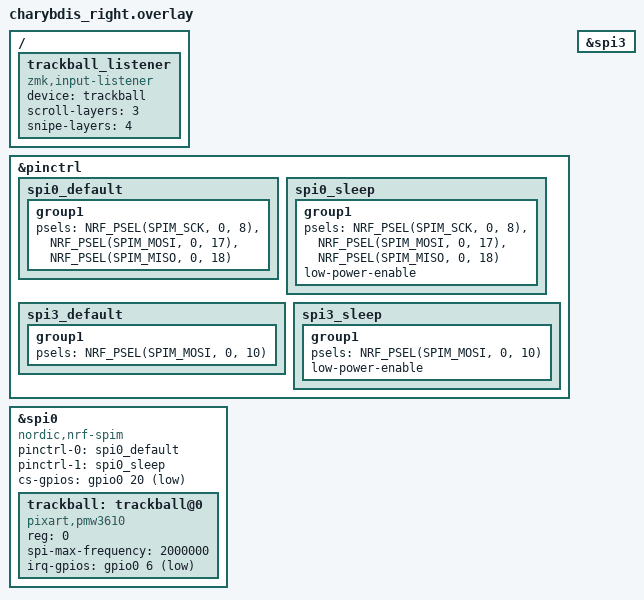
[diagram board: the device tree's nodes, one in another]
/*
 * Copyright (c) 2020 ZMK Contributors
 * SPDX-License-Identifier: MIT
 */

#include "charybdis.dtsi"

// ... (other nodes: &default_transform, &kscan0, &kscan_pointer_input) ...

// trackball & RGB PINCTRL (MUST BE A SINGLE BLOCK)
&pinctrl {
    // 1. SPI0 (Trackball)
    spi0_default: spi0_default {
        group1 {
            // FIX: MISO pin P0.18
            psels = <NRF_PSEL(SPIM_SCK, 0, 8)>,
                    <NRF_PSEL(SPIM_MOSI, 0, 17)>,
                    <NRF_PSEL(SPIM_MISO, 0, 18)>; 
        };
    };
    spi0_sleep: spi0_sleep {
        group1 {
            // FIX: MISO pin P0.18
            psels = <NRF_PSEL(SPIM_SCK, 0, 8)>,
                    <NRF_PSEL(SPIM_MOSI, 0, 17)>,
                    <NRF_PSEL(SPIM_MISO, 0, 18)>; 
            low-power-enable;
        };
    };

    // 2. SPI3 (RGB Bus)
    spi3_default: spi3_default {
        group1 {
            psels = <NRF_PSEL(SPIM_MOSI, 0, 10)>;
        };
    };
    spi3_sleep: spi3_sleep {
        group1 {
            psels = <NRF_PSEL(SPIM_MOSI, 0, 10)>;
            low-power-enable;
        };
    };
}; // <--- SEMICOLON AND CLOSING BRACE ARE CRITICAL

&spi0 {
    status = "okay";
    compatible = "nordic,nrf-spim";
    pinctrl-0 = <&spi0_default>;
    pinctrl-1 = <&spi0_sleep>;
    pinctrl-names = "default", "sleep";
    cs-gpios = <&gpio0 20 GPIO_ACTIVE_LOW>;

    trackball: trackball@0 {
        status = "okay";
        compatible = "pixart,pmw3610";
        reg = <0>;
        spi-max-frequency = <2000000>;
        irq-gpios = <&gpio0 6 (GPIO_ACTIVE_LOW | GPIO_PULL_UP)>;
        // ⬅️ REMOVED scroll-layers & snipe-layers here
    }; // <--- CLOSING BRACE AND SEMICOLON
};

&spi3 {
    // ... (Your SPI3 RGB configuration) ...
};

// ⬅️ DELETE ANY REMAINING &pinctrl { ... } BLOCK HERE

/ {
    trackball_listener {
        compatible = "zmk,input-listener";
        device = <&trackball>;
        // ⬅️ ADD ZMK LAYER PROPERTIES HERE
        scroll-layers = <3>;
        snipe-layers = <4>;
    }; // <--- CLOSING BRACE AND SEMICOLON
};
